# BlueNRG2 register map
Vendor: STMicroelectronics; Series: BlueNRG2; File version: 1.2.1
CPU: CM0 r0p0, little endian, no MPU, no FPU, 2 interrupt priority bits
Registers are 32-bit, read-write, reset 0x0 unless marked. A register's access mark holds for its fields unless they carry their own. Offsets are from the block's base; [hi:lo] are bit positions; {n}, {i} and the like mark numbered series.

## DMA
Base 0xA0000000
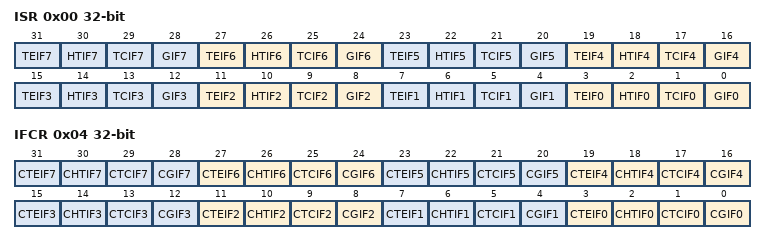
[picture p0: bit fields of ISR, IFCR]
0x00 ISR ro — DMA interrupt status register
  [4n+3] TEIF{n} (n=0..7) — Channel {n} transfer error flag. This bit is set by hardware. It is cleared by software writing 1 to the corresponding bit in the IFCR register.<ul><li>0: No transfer error (TE) event on channel {n}.</li><li>1: A transfer error (TE) occurred on channel {n}.</li></ul>
  [4n+2] HTIF{n} (n=0..7) — Channel {n} half transfer flag. This bit is set by hardware. It is cleared by software writing 1 to the corresponding bit in the IFCR register.<ul><li>0: No half transfer (HT) event on channel {n}.</li><li>1: A half transfer (HT) event occurred on channel {n}.</li></ul>
  [4n+1] TCIF{n} (n=0..7) — Channel {n} transfer complete flag. This bit is set by hardware. It is cleared by software writing 1 to the corresponding bit in the IFCR register.<ul><li>0: No transfer complete (TC) on channel {n}.</li><li>1: A transfer complete (TC) occurred on channel {n}.</li></ul>
  [4n] GIF{n} (n=0..7) — Channel {n} global interrupt flag. This bit is set by hardware. It is cleared by software writing 1 to the corresponding bit in the IFCR register.<ul><li>0: No TE, HT or TC event on channel {n}.</li><li>1: A TE, HT or TC event occurred on channel {n}.</li></ul>
0x04 IFCR wo — DMA interrupt flag clear register
  [4n+3] CTEIF{n} (n=0..7) — Channel {n} transfer error flag. This bit is set by software.<ul><li>0: No effect.</li><li>1: Clears the corresponding TEIF flag in the ISR register.</li></ul>
  [4n+2] CHTIF{n} (n=0..7) — Channel {n} half transfer flag. This bit is set by software.<ul><li>0: No effect.</li><li>1: Clears the corresponding HTIF flag in the ISR register.</li></ul>
  [4n+1] CTCIF{n} (n=0..7) — Channel {n} transfer complete flag. This bit is set by software.<ul><li>0: No effect.</li><li>1: Clears the corresponding TCIF flag in the ISR register.</li></ul>
  [4n] CGIF{n} (n=0..7) — Channel {n} global interrupt flag. This bit is set by software.<ul><li>0: No effect.</li><li>1: Clears the GIF, TEIF, HTIF and TCIF flags in the ISR register.</li></ul>

## RNG
Base 0xB0000000
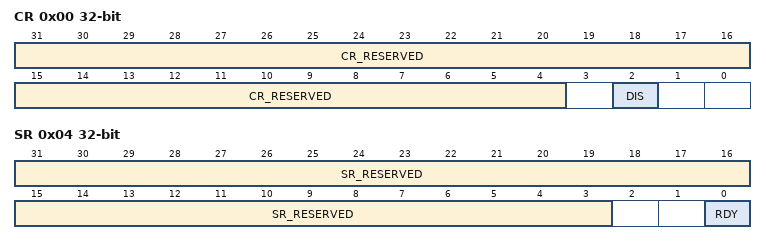
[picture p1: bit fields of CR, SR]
0x00 CR (reset mask 0xFFFF) — RNG configuration register
  [31:4] CR_RESERVED ro — CR not used bitfield.
  [2] DIS — Set the state of the random number generator.<ul><li>0: RNG is enable.</li><li>1: RNG is disabled. The internal free-running oscillators are put in power-down mode and the RNG clock is stopped at the input of the block.</li></ul>
0x04 SR ro (reset mask 0xFFFF) — RNG status register
  [31:3] SR_RESERVED — SR not used bitfield.
  [0] RDY — New random value ready.<ul><li>0: The RNG_VAL register value is not yet valid. If performing a read access to VAL, the host will be put on hold (by wait-states insertion on the AHB bus) until a random value is available.</li><li>1: The VAL register contains a valid random number.</li></ul>This bit remains at 0 when the RNG is disabled (RNGDIS bit = 1b in CR)
0x08 VAL ro (reset mask 0xFFFF) — RNG 16 bit random value

## PKA
Base 0xC0000000
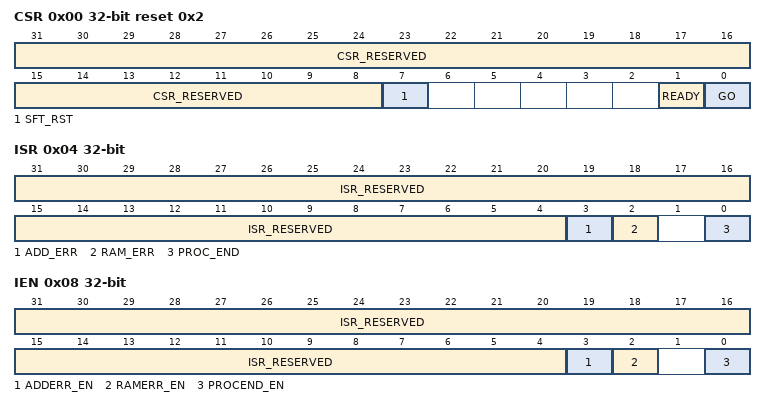
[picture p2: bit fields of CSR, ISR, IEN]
0x00 CSR reset 0x2 (reset mask 0xFFFF) — Command and status register
  [31:8] CSR_RESERVED ro — CSR not used bitfield.
  [7] SFT_RST wo — PKA software reset:<ul><li>0: has no effect.</li><li>1: reset the PKA peripheral.</li></ul>After this bitfield is written to 1, it must be written back to zero manually.
  [1] READY ro — PKA readiness status:<ul><li>0: the PKA is computing. It is not ready.</li><li>1: the PKA is ready to start a new processing.</li></ul>The rising edge of the READY bit set the PROC_END flag in the ISR register.
  [0] GO wo — PKA start processing command:<ul><li>0: has no effect.</li><li>1: starts the processing.</li></ul>After this bitfield is written to 1, it must be written back to zero manually.
0x04 ISR — Interrupt status register
  [31:4] ISR_RESERVED ro — ISR not used bitfield.
  [3] ADD_ERR — AHB address error interrupt. When read:<ul><li>0: All AHB read or write access to the PKA RAM occurred in a mapped address range.</li><li>1: All AHB read or write access to the PKA RAM occurred in an unmapped address range.</li></ul>When written:<ul><li>0: no effect.</li><li>1: clears the AHB Address error interrupt.</li></ul>
  [2] RAM_ERR — RAM read / write access error interrupt. When read:<ul><li>0: All AHB read or write access to the PKA RAM occurred while the PKA was stopped.</li><li>1: All the AHB read or write access to the PKA RAM occurred while the PKA was operating and using the internal RAM. Those read or write could not succeed as the PKA internal RAM is disconnected from the AHB bus when the PKA is operating (READY bit low).</li></ul>When written:<ul><li>0: no effect.</li><li>1: clears the RAM access error interrupt.</li></ul>
  [0] PROC_END — PKA process ending interrupt. When read:<ul><li>0: no event.</li><li>1: PKA process is ended.</li></ul>When written:<ul><li>0: no effect.</li><li>1: clears the PKA process ending interrupt.</li></ul>
0x08 IEN — Interrupt enable register
  [31:4] ISR_RESERVED ro — ISR not used bitfield.
  [3] ADDERR_EN — AHB address error interrupt enable.<ul><li>0: interrupt disabled.</li><li>1: interrupt enabled.</li></ul>
  [2] RAMERR_EN — RAM access error interrupt enable.<ul><li>0: interrupt disabled.</li><li>1: interrupt enabled.</li></ul>
  [0] PROCEND_EN — Process ended interrupt enable.<ul><li>0: interrupt disabled.</li><li>1: interrupt enabled.</li></ul>

## ROM_INFO — ROM information
Base 0x10000000
0x10 BOOTLOADER_VERSION ro
0x18 FLASH_WRITE ro — FLASH write function
0x1C FLASH_ERASE ro — FLASH erase function
0x20 BOOTLOADER ro — Bootloader entry point
0x7B0 BLD_TRIM ro — BLD trimming value
0x7B4 ADC_BLD_1V8_OFFSET ro
0x7B8 ADC_BLD_1V8_VALUE ro
0x7BC ADC_BLD_2V7_OFFSET ro
0x7C0 ADC_BLD_2V7_VALUE ro
0x7C4 ADC_BLD_3V6_OFFSET ro
0x7C8 ADC_BLD_3V6_VALUE ro
0x7CC ADC_SE2_0V_OFFSET ro
0x7D0 ADC_SE2_0V_VALUE ro
0x7D4 ADC_SE2_1V8_OFFSET ro
0x7D8 ADC_SE2_1V8_VALUE ro
0x7DC ADC_SE2_3V6_OFFSET ro
0x7E0 ADC_SE2_3V6_VALUE ro
0x7E4 LDO1V2_TRIMM_CODE 16-bit ro — LDO 1V2 trimming code
0x7E6 LDO1V2_TRIMMING_CODE_CHECK_BYTES 16-bit ro
0x7E8 RCO_TRIMMING_CODE 16-bit ro
0x7EA RCO_TRIMMING_CODE_CHECK_BYTES 16-bit ro
0x7F4 UNIQUE_ID_1 8-bit ro — Unique ID 1st byte
0x7F5 UNIQUE_ID_2 8-bit ro — Unique ID 2nd byte
0x7F6 UNIQUE_ID_3 8-bit ro — Unique ID 3rd byte
{0x7F3+i} UNIQUE_ID_{i} 8-bit ro (i=4..6) — Unique ID {i}th byte
0x7FA UNIQUE_ID_CHECK_CODE 16-bit ro
0x7FC FLASH_PROTECTION_DISABLED ro — ROM Lock Protection (not locked)
